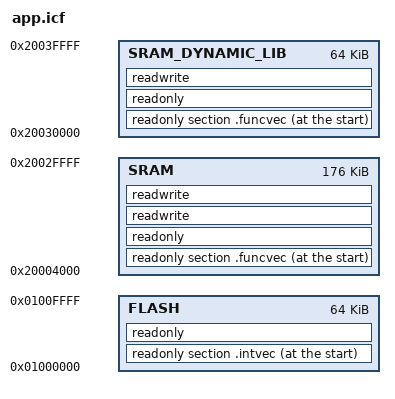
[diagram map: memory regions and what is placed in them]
//*****************************************************************************
// app1.icf
//
// IAR Linker configuration file.
//
// Copyright (C) 2014 Texas Instruments Incorporated - http://www.ti.com/ 
// 
// 
//  Redistribution and use in source and binary forms, with or without 
//  modification, are permitted provided that the following conditions 
//  are met:
//
//    Redistributions of source code must retain the above copyright 
//    notice, this list of conditions and the following disclaimer.
//
//    Redistributions in binary form must reproduce the above copyright
//    notice, this list of conditions and the following disclaimer in the 
//    documentation and/or other materials provided with the   
//    distribution.
//
//    Neither the name of Texas Instruments Incorporated nor the names of
//    its contributors may be used to endorse or promote products derived
//    from this software without specific prior written permission.
//
//  THIS SOFTWARE IS PROVIDED BY THE COPYRIGHT HOLDERS AND CONTRIBUTORS 
//  "AS IS" AND ANY EXPRESS OR IMPLIED WARRANTIES, INCLUDING, BUT NOT 
//  LIMITED TO, THE IMPLIED WARRANTIES OF MERCHANTABILITY AND FITNESS FOR
//  A PARTICULAR PURPOSE ARE DISCLAIMED. IN NO EVENT SHALL THE COPYRIGHT 
//  OWNER OR CONTRIBUTORS BE LIABLE FOR ANY DIRECT, INDIRECT, INCIDENTAL, 
//  SPECIAL, EXEMPLARY, OR CONSEQUENTIAL DAMAGES (INCLUDING, BUT NOT 
//  LIMITED TO, PROCUREMENT OF SUBSTITUTE GOODS OR SERVICES; LOSS OF USE,
//  DATA, OR PROFITS; OR BUSINESS INTERRUPTION) HOWEVER CAUSED AND ON ANY
//  THEORY OF LIABILITY, WHETHER IN CONTRACT, STRICT LIABILITY, OR TORT 
//  (INCLUDING NEGLIGENCE OR OTHERWISE) ARISING IN ANY WAY OUT OF THE USE 
//  OF THIS SOFTWARE, EVEN IF ADVISED OF THE POSSIBILITY OF SUCH DAMAGE.
//
//*****************************************************************************

//
// Define a memory region that covers the entire 4 GB addressable space of the
// processor.
//
define memory mem with size = 4G;

//
// Define a region for the on-chip flash.
//
define region FLASH = mem:[from 0x01000000 to 0x0100FFFF];

//
// Define a region for the on-chip SRAM.
// In project Define CC3200_ES_1_2_1 = 1 for CC3200 ES 1.21
// 			  Define CC3200_ES_1_2_1 = 0 for CC3200 ES 1.32 onward
//
if (!isdefinedsymbol(CC3200_ES_1_2_1))
{
	define region SRAM = mem:[from 0x20000000 to 0x2002FFFF];
}
else if(CC3200_ES_1_2_1)
{
	define region SRAM = mem:[from 0x20000000 to 0x2002FFFF];
	place at start of SRAM	{ readonly section .funcvec };	
}
else
{
	define region SRAM = mem:[from 0x20004000 to 0x2002FFFF];
	define region SRAM_DYNAMIC_LIB = mem:[from 0x20030000 to 0x2003FFFF];
	
	place at start of SRAM_DYNAMIC_LIB	{ readonly section .funcvec };	
}

//-----------------------------------------------------------
initialize by copy { readwrite };
//-----------------------------------------------------------

//
// Place the interrupt vectors at the start of flash.
// Define Flash = 0 if application doesn't use Flash memory
// else define Flash = 1 
//
if (!isdefinedsymbol(Flash))
{
	//
	// Place the remainder of the read-only items into flash.
	//
	place in SRAM_DYNAMIC_LIB { readonly };

	//
	// Place all read/write items into SRAM_DYNAMIC_LIB.
	//
	place in SRAM_DYNAMIC_LIB { readwrite };
}
else if (!Flash)
{
	//
	// Place the remainder of the read-only items into flash.
	//
	place in SRAM { readonly };

	//
	// Place all read/write items into SRAM.
	//
	place in SRAM { readwrite };
}
else
{
	//-----------------------------------------------------------
	place at start of FLASH { readonly section .intvec };
	//-----------------------------------------------------------

	//
	// Place the remainder of the read-only items into flash.
	//
	place in FLASH { readonly };

	//
	// Place all read/write items into SRAM.
	//
	place in SRAM { readwrite };
}

